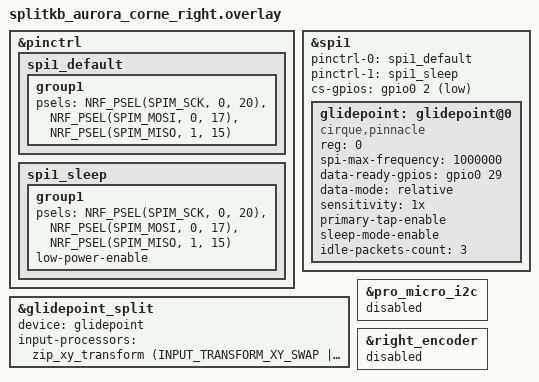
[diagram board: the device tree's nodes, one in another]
#include "splitkb_aurora_corne.dtsi"
#include <dt-bindings/zmk/input_transform.h>
#include <input/processors/transform.dtsi>

&pinctrl {
    spi1_default: spi1_default {
        group1 {
            psels = <NRF_PSEL(SPIM_SCK, 0, 20)>,
                    <NRF_PSEL(SPIM_MOSI, 0, 17)>,
                    <NRF_PSEL(SPIM_MISO, 1, 15)>;
        };
    };

    spi1_sleep: spi1_sleep {
        group1 {
            psels = <NRF_PSEL(SPIM_SCK, 0, 20)>,
                    <NRF_PSEL(SPIM_MOSI, 0, 17)>,
                    <NRF_PSEL(SPIM_MISO, 1, 15)>;
            low-power-enable;
        };
    };
};

&spi1 {
    status = "okay";
    pinctrl-0 = <&spi1_default>;
    pinctrl-1 = <&spi1_sleep>;
    pinctrl-names = "default", "sleep";
    cs-gpios = <&gpio0 2 GPIO_ACTIVE_LOW>;

    glidepoint: glidepoint@0 {
        compatible = "cirque,pinnacle";
        reg = <0>;
        spi-max-frequency = <1000000>;
        status = "okay";
        data-ready-gpios = <&gpio0 29 GPIO_ACTIVE_HIGH>;
        data-mode = "relative";
        sensitivity = "1x";
        primary-tap-enable;
        sleep-mode-enable;
        idle-packets-count = <3>;
    };
};

&glidepoint_split {
    device = <&glidepoint>;
    input-processors = <&zip_xy_transform (INPUT_TRANSFORM_XY_SWAP | INPUT_TRANSFORM_X_INVERT | INPUT_TRANSFORM_Y_INVERT)>;
};

// OLED unused; its I2C pins (SDA=P0.17, SCL=P0.20) are reused by the trackpad SPI (MOSI/SCK).
&pro_micro_i2c { status = "disabled"; };

// The shield enables the right encoder on pro_micro 19/18 (P0.02/P1.15),
// which are the trackpad CS and MISO pins. No encoder is fitted.
&right_encoder { status = "disabled"; };
